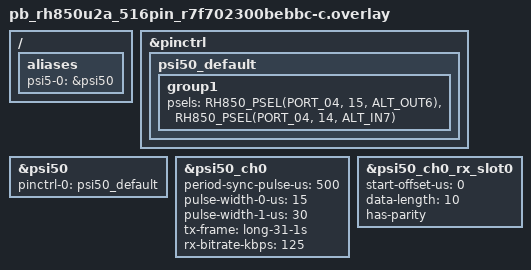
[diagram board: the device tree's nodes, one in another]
/*
 * Copyright (c) 2026 Renesas Electronics Corporation
 *
 * SPDX-License-Identifier: Apache-2.0
 */

/ {
	aliases {
		psi5-0 = &psi50;
	};
};

/*
 * PSI5 pin mux for U2A 516-pin, taken from the U2A pin function table.
 *
 *   Unit   RX pin  (func)     TX pin  (func)      Ball RX/TX
 *   PSI50  P04_14  ALT_IN7    P04_15  ALT_OUT6    AD22 / AE23
 *   PSI51  P04_12  ALT_IN6    P04_13  ALT_OUT6    AD21 / AE22
 *   PSI52  P05_2   ALT_IN5    P05_3   ALT_OUT5    J25  / J24
 *   PSI53  P05_4   ALT_IN5    P05_6   ALT_OUT5    H25  / G24
 */

&pinctrl {
	psi50_default: psi50_default {
		group1 {
			psels = <RH850_PSEL(PORT_04, 15, ALT_OUT6)>,	/* PSI50TX */
				<RH850_PSEL(PORT_04, 14, ALT_IN7)>;	/* PSI50RX */
		};
	};
};

&psi50 {
	pinctrl-0 = <&psi50_default>;
	pinctrl-names = "default";
	status = "okay";
};

&psi50_ch0 {
	period-sync-pulse-us = <500>;
	pulse-width-0-us = <15>;
	pulse-width-1-us = <30>;
	/* Long frame like the upstream NXP overlay: FRMFORMAT = 010, 16-bit TXDATA, sends 0x1234 */
	tx-frame = "long-31-1s";
	rx-bitrate-kbps = <125>;
	status = "okay";
};

&psi50_ch0_rx_slot0 {
	start-offset-us = <0>;
	data-length = <10>;
	has-parity;
	status = "okay";
};
